AUTOSAR XML (schema 4-0-3)
standard types defined: Boolean, UInt16, UInt32, UInt8
package /AUTOSAR_Platform/DataConstrs
  range DC_Boolean: raw 0..1
  range DC_UInt16: raw 0..65535
  range DC_UInt8: raw 0..255
package /PATAC/MSM/ComponentTypes
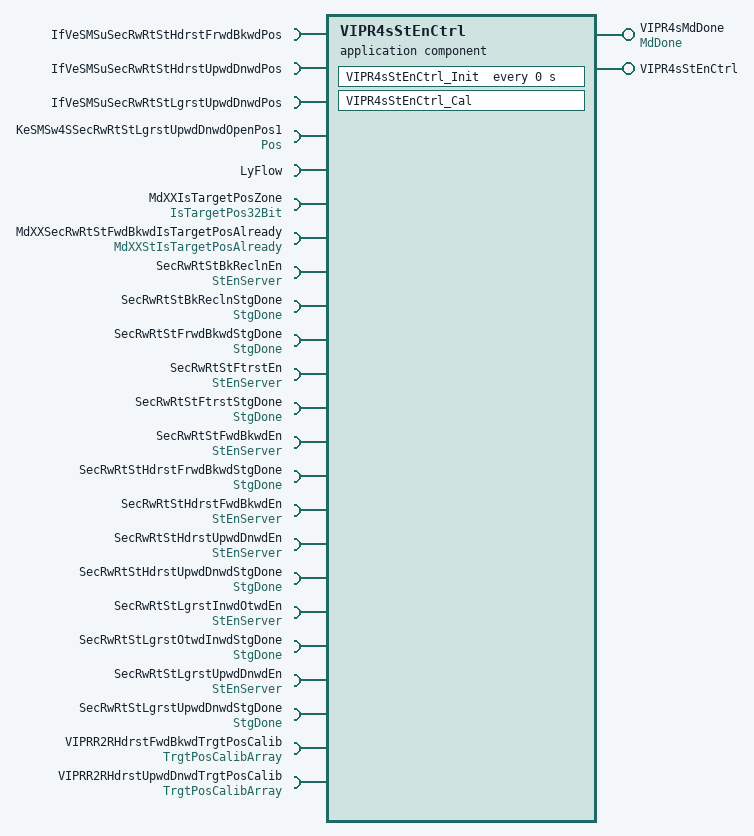
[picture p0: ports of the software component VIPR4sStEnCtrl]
  application sw component type VIPR4sStEnCtrl
    provide port VIPR4sMdDone: nonqueued-sender-com-spec{data-element=MdDone/Val, init-value=0}, provided-interface=MdDone
    provide port VIPR4sStEnCtrl: server-com-spec{operation=VIPR4sStEnCtrl/Cal, queue-length=1}, provided-interface=VIPR4sStEnCtrl
    23 x require port:
      IfVeSMSuSecRwRtStHdrstFrwdBkwdPos: nonqueued-receiver-com-spec{data-element=IfVeSMSuSecRwRtStHdrstFrwdBkwdPos/Val, filter=data-filter-type=ALWAYS, init-value=0}, required-interface=IfVeSMSuSecRwRtStHdrstFrwdBkwdPos
      IfVeSMSuSecRwRtStHdrstUpwdDnwdPos: nonqueued-receiver-com-spec{data-element=IfVeSMSuSecRwRtStHdrstUpwdDnwdPos/Val, filter=data-filter-type=ALWAYS, init-value=0}, required-interface=IfVeSMSuSecRwRtStHdrstUpwdDnwdPos
      IfVeSMSuSecRwRtStLgrstUpwdDnwdPos: nonqueued-receiver-com-spec{data-element=IfVeSMSuSecRwRtStLgrstUpwdDnwdPos/Val, filter=data-filter-type=ALWAYS, init-value=0}, required-interface=IfVeSMSuSecRwRtStLgrstUpwdDnwdPos
      KeSMSw4SSecRwRtStLgrstUpwdDnwdOpenPos1: parameter-require-com-spec{init-value=0, parameter=Val}, required-interface=Pos
      LyFlow: client-com-spec=LyFlow/Cal, required-interface=LyFlow
      MdXXIsTargetPosZone: nonqueued-receiver-com-spec{data-element=IsTargetPos32Bit/Val, filter=data-filter-type=ALWAYS, init-value=0}, required-interface=IsTargetPos32Bit
      MdXXSecRwRtStFwdBkwdIsTargetPosAlready: nonqueued-receiver-com-spec{data-element=MdXXStIsTargetPosAlready/Val, filter=data-filter-type=ALWAYS, init-value=0}, required-interface=MdXXStIsTargetPosAlready
      SecRwRtStBkReclnEn: required-com-specs=[Clear, Get, Set], required-interface=StEnServer
      SecRwRtStBkReclnStgDone: nonqueued-receiver-com-spec{data-element=StgDone/Val, filter=data-filter-type=ALWAYS, init-value=0}, required-interface=StgDone
      SecRwRtStFrwdBkwdStgDone: nonqueued-receiver-com-spec{data-element=StgDone/Val, filter=data-filter-type=ALWAYS, init-value=0}, required-interface=StgDone
      SecRwRtStFtrstEn: required-com-specs=[Clear, Get, Set], required-interface=StEnServer
      SecRwRtStFtrstStgDone: nonqueued-receiver-com-spec{data-element=StgDone/Val, filter=data-filter-type=ALWAYS, init-value=0}, required-interface=StgDone
      SecRwRtStFwdBkwdEn: required-com-specs=[Clear, Get, Set], required-interface=StEnServer
      SecRwRtStHdrstFrwdBkwdStgDone: nonqueued-receiver-com-spec{data-element=StgDone/Val, filter=data-filter-type=ALWAYS, init-value=0}, required-interface=StgDone
      SecRwRtStHdrstFwdBkwdEn: required-com-specs=[Clear, Get, Set], required-interface=StEnServer
      SecRwRtStHdrstUpwdDnwdEn: required-com-specs=[Clear, Get, Set], required-interface=StEnServer
      SecRwRtStHdrstUpwdDnwdStgDone: nonqueued-receiver-com-spec{data-element=StgDone/Val, filter=data-filter-type=ALWAYS, init-value=0}, required-interface=StgDone
      SecRwRtStLgrstInwdOtwdEn: required-com-specs=[Clear, Get, Set], required-interface=StEnServer
      SecRwRtStLgrstOtwdInwdStgDone: nonqueued-receiver-com-spec{data-element=StgDone/Val, filter=data-filter-type=ALWAYS, init-value=0}, required-interface=StgDone
      SecRwRtStLgrstUpwdDnwdEn: required-com-specs=[Clear, Get, Set], required-interface=StEnServer
      SecRwRtStLgrstUpwdDnwdStgDone: nonqueued-receiver-com-spec{data-element=StgDone/Val, filter=data-filter-type=ALWAYS, init-value=0}, required-interface=StgDone
      VIPRR2RHdrstFwdBkwdTrgtPosCalib: nonqueued-receiver-com-spec{data-element=TrgtPosArray, filter=data-filter-type=ALWAYS, init-value=[4095, 4095, 4095]}, required-interface=TrgtPosCalibArray
      VIPRR2RHdrstUpwdDnwdTrgtPosCalib: nonqueued-receiver-com-spec{data-element=TrgtPosArray, filter=data-filter-type=ALWAYS, init-value=[4095, 4095, 4095]}, required-interface=TrgtPosCalibArray
    behavior VIPR4sStEnCtrl_InternalBehavior
      operation invoked event OIT_VIPR4sStEnCtrl_Cal_VIPR4sStEnCtrl_Cal: start-on-event=VIPR4sStEnCtrl_Cal, operation=VIPR4sStEnCtrl.Cal
      timing event VIPR4sStEnCtrl_InitEvent: start-on-event=VIPR4sStEnCtrl_Init, period=0
      runnable VIPR4sStEnCtrl_Cal
        data-receive-point-by-arguments:
          14 x access:
            REC_IfVeSMSuSecRwRtStHdrstFrwdBkwdPos_Val: accessed-variable=IfVeSMSuSecRwRtStHdrstFrwdBkwdPos.Val
            REC_IfVeSMSuSecRwRtStHdrstUpwdDnwdPos_Val: accessed-variable=IfVeSMSuSecRwRtStHdrstUpwdDnwdPos.Val
            REC_IfVeSMSuSecRwRtStLgrstUpwdDnwdPos_Val: accessed-variable=IfVeSMSuSecRwRtStLgrstUpwdDnwdPos.Val
            REC_MdXXIsTargetPosZone_Val: accessed-variable=MdXXIsTargetPosZone.Val
            REC_MdXXSecRwRtStFwdBkwdIsTargetPosAlready_Val: accessed-variable=MdXXSecRwRtStFwdBkwdIsTargetPosAlready.Val
            REC_SecRwRtStBkReclnStgDone_Val: accessed-variable=SecRwRtStBkReclnStgDone.Val
            REC_SecRwRtStFrwdBkwdStgDone_Val: accessed-variable=SecRwRtStFrwdBkwdStgDone.Val
            REC_SecRwRtStFtrstStgDone_Val: accessed-variable=SecRwRtStFtrstStgDone.Val
            REC_SecRwRtStHdrstFrwdBkwdStgDone_Val: accessed-variable=SecRwRtStHdrstFrwdBkwdStgDone.Val
            REC_SecRwRtStHdrstUpwdDnwdStgDone_Val: accessed-variable=SecRwRtStHdrstUpwdDnwdStgDone.Val
            REC_SecRwRtStLgrstOtwdInwdStgDone_Val: accessed-variable=SecRwRtStLgrstOtwdInwdStgDone.Val
            REC_SecRwRtStLgrstUpwdDnwdStgDone_Val: accessed-variable=SecRwRtStLgrstUpwdDnwdStgDone.Val
            REC_VIPRR2RHdrstFwdBkwdTrgtPosCalib_TrgtPosArray: accessed-variable=VIPRR2RHdrstFwdBkwdTrgtPosCalib.TrgtPosArray
            REC_VIPRR2RHdrstUpwdDnwdTrgtPosCalib_TrgtPosArray: accessed-variable=VIPRR2RHdrstUpwdDnwdTrgtPosCalib.TrgtPosArray
        data-send-points:
          access SEND_VIPR4sMdDone_Val: accessed-variable=VIPR4sMdDone.Val
        parameter access PA_KeSMSw4SSecRwRtStLgrstUpwdDnwdOpenPos1_Val: accessed-parameter=KeSMSw4SSecRwRtStLgrstUpwdDnwdOpenPos1.Val
        15 x sync call, all with timeout=0:
          SC_LyFlow_Cal: operation=LyFlow.Cal
          SC_SecRwRtStBkReclnEn_Clear: operation=SecRwRtStBkReclnEn.Clear
          SC_SecRwRtStBkReclnEn_Set: operation=SecRwRtStBkReclnEn.Set
          SC_SecRwRtStFtrstEn_Clear: operation=SecRwRtStFtrstEn.Clear
          SC_SecRwRtStFtrstEn_Set: operation=SecRwRtStFtrstEn.Set
          SC_SecRwRtStFwdBkwdEn_Clear: operation=SecRwRtStFwdBkwdEn.Clear
          SC_SecRwRtStFwdBkwdEn_Set: operation=SecRwRtStFwdBkwdEn.Set
          SC_SecRwRtStHdrstFwdBkwdEn_Clear: operation=SecRwRtStHdrstFwdBkwdEn.Clear
          SC_SecRwRtStHdrstFwdBkwdEn_Set: operation=SecRwRtStHdrstFwdBkwdEn.Set
          SC_SecRwRtStHdrstUpwdDnwdEn_Clear: operation=SecRwRtStHdrstUpwdDnwdEn.Clear
          SC_SecRwRtStHdrstUpwdDnwdEn_Set: operation=SecRwRtStHdrstUpwdDnwdEn.Set
          SC_SecRwRtStLgrstInwdOtwdEn_Clear: operation=SecRwRtStLgrstInwdOtwdEn.Clear
          SC_SecRwRtStLgrstInwdOtwdEn_Set: operation=SecRwRtStLgrstInwdOtwdEn.Set
          SC_SecRwRtStLgrstUpwdDnwdEn_Clear: operation=SecRwRtStLgrstUpwdDnwdEn.Clear
          SC_SecRwRtStLgrstUpwdDnwdEn_Set: operation=SecRwRtStLgrstUpwdDnwdEn.Set
      runnable VIPR4sStEnCtrl_Init
        parameter access PA_KeSMSw4SSecRwRtStLgrstUpwdDnwdOpenPos1_Val: accessed-parameter=KeSMSw4SSecRwRtStLgrstUpwdDnwdOpenPos1.Val
  swc implementation VIPR4sStEnCtrl_Implementation: behavior=VIPR4sStEnCtrl_InternalBehavior
    code-descriptors:
      code Default: artifact-descriptors=autosar-engineering-object={short-label=Default, category=SWSRC}
package /PATAC/MSM/ModeAdjust/CalPortInterface
  parameter interface Pos
    parameter data prototype Val: sw-calibration-access=READ-WRITE, type=UInt16
package /PATAC/MSM/ModeAdjust/DataType
  impl type TrgtPosCalibArray: category=ARRAY, sw-calibration-access=READ-ONLY, type-emitter=RTE  # 0:pos 1:max 2:min
    element Element: array-size=3, array-size-semantics=FIXED-SIZE, implementation-data-type=UInt16, invalid-value=0
package /PATAC/MSM/ModeAdjust/PortInterface
  client server interface LyFlow
    operation Cal
      20 x arg, all with server-argument-impl-policy=USE-ARGUMENT-TYPE:
        BkReclnStgDone: type=Boolean, direction=IN
        LgrstUpwdDnwdPos: type=UInt16, direction=IN
        LgrstUpwdDnwdOpenPos1: type=UInt16, direction=IN
        LgrstUpwdStgDone: type=Boolean, direction=IN
        FtrstStgDone: type=Boolean, direction=IN
        LgrstInwdStgDone: type=Boolean, direction=IN
        Chkhdflg: type=Boolean, direction=IN
        HdrstUpwdDnwdStgDone: type=Boolean, direction=IN
        HdrstFrwdBkwdStgDone: type=Boolean, direction=IN
        FwdBkwdStgDone: type=Boolean, direction=IN
        FwdBkwdIsPosAlready: type=Boolean, direction=IN
        Failflg: type=Boolean, direction=OUT
        BkReclnEn: type=Boolean, direction=OUT
        HdrstUpwdEn: type=Boolean, direction=OUT
        HdrstFrwdEn: type=Boolean, direction=OUT
        LgrstUpwdDnwdEn: type=Boolean, direction=OUT
        FtrstEn: type=Boolean, direction=OUT
        LgrstInwdOtwdEn: type=Boolean, direction=OUT
        FwdBkwdEn: type=Boolean, direction=OUT
        FailBkwd: type=Boolean, direction=OUT
  client server interface StEnServer
    operation Clear
      arg data: type=UInt8, direction=IN, server-argument-impl-policy=USE-ARGUMENT-TYPE
    operation Get
      arg data: type=UInt32, direction=OUT, server-argument-impl-policy=USE-ARGUMENT-TYPE
    operation Set
      arg data: type=UInt8, direction=IN, server-argument-impl-policy=USE-ARGUMENT-TYPE
  client server interface VIPR4sStEnCtrl
    operation Cal
  5 x sender receiver interface:
    IsTargetPos32Bit: invalidation-policy{data-element=IsTargetPos32Bit/Val, handle-invalid=DONT-INVALIDATE}
      data Val: type=UInt32
    MdDone: invalidation-policy{data-element=MdDone/Val, handle-invalid=DONT-INVALIDATE}
      data Val: type=UInt8
    MdXXStIsTargetPosAlready: invalidation-policy{data-element=MdXXStIsTargetPosAlready/Val, handle-invalid=DONT-INVALIDATE}
      data Val: type=UInt32
    StgDone: invalidation-policy{data-element=StgDone/Val, handle-invalid=DONT-INVALIDATE}
      data Val: type=Boolean
    TrgtPosCalibArray: invalidation-policy{data-element=TrgtPosArray, handle-invalid=DONT-INVALIDATE}
      data TrgtPosArray: type=TrgtPosCalibArray  # 0:Pos 1:Max 2:Min
package /PATAC/MSM/PortInterfaces
  sender receiver interface IfVeSMSuSecRwRtStHdrstFrwdBkwdPos: invalidation-policy{data-element=IfVeSMSuSecRwRtStHdrstFrwdBkwdPos/Val, handle-invalid=DONT-INVALIDATE}
    data Val: type=UInt16
  sender receiver interface IfVeSMSuSecRwRtStHdrstUpwdDnwdPos: invalidation-policy{data-element=IfVeSMSuSecRwRtStHdrstUpwdDnwdPos/Val, handle-invalid=DONT-INVALIDATE}
    data Val: type=UInt16
  sender receiver interface IfVeSMSuSecRwRtStLgrstUpwdDnwdPos: invalidation-policy{data-element=IfVeSMSuSecRwRtStLgrstUpwdDnwdPos/Val, handle-invalid=DONT-INVALIDATE}
    data Val: type=UInt16
